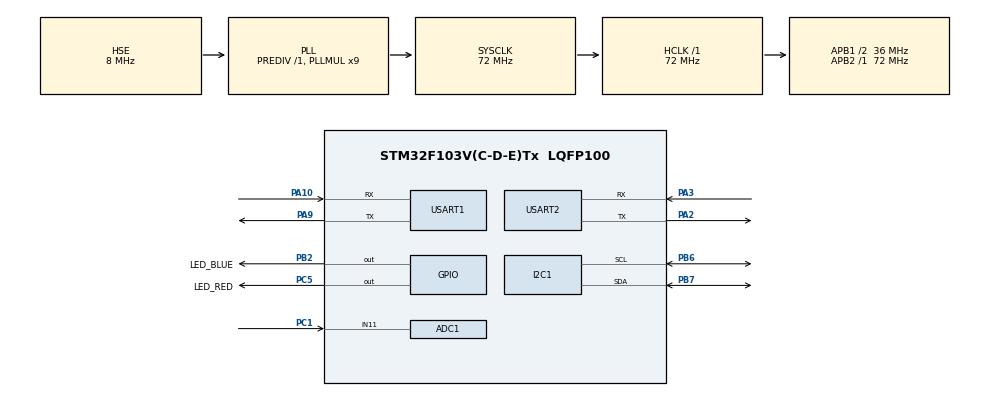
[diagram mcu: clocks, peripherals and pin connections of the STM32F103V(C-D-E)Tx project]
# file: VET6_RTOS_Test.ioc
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ADC1.Channel-2\#ChannelRegularConversion=ADC_CHANNEL_11
ADC1.NbrOfConversionFlag=1
ADC1.Rank-2\#ChannelRegularConversion=1
ADC1.SamplingTime-2\#ChannelRegularConversion=ADC_SAMPLETIME_1CYCLE_5
ADC1.master=1
Dma.Request0=USART1_RX
Dma.Request1=USART1_TX
Dma.Request2=USART2_RX
Dma.Request3=USART2_TX
Dma.USART1_RX.0.Direction=DMA_PERIPH_TO_MEMORY
Dma.USART1_RX.0.Instance=DMA1_Channel5
Dma.USART1_RX.0.MemDataAlignment=DMA_MDATAALIGN_BYTE
Dma.USART1_RX.0.MemInc=DMA_MINC_ENABLE
Dma.USART1_RX.0.Mode=DMA_NORMAL
Dma.USART1_RX.0.PeriphDataAlignment=DMA_PDATAALIGN_BYTE
Dma.USART1_RX.0.PeriphInc=DMA_PINC_DISABLE
Dma.USART1_RX.0.Priority=DMA_PRIORITY_LOW
Dma.USART1_TX.1.Direction=DMA_MEMORY_TO_PERIPH
Dma.USART1_TX.1.Instance=DMA1_Channel4
Dma.USART1_TX.1.MemDataAlignment=DMA_MDATAALIGN_BYTE
Dma.USART1_TX.1.MemInc=DMA_MINC_ENABLE
Dma.USART1_TX.1.Mode=DMA_NORMAL
Dma.USART1_TX.1.PeriphDataAlignment=DMA_PDATAALIGN_BYTE
Dma.USART1_TX.1.PeriphInc=DMA_PINC_DISABLE
Dma.USART1_TX.1.Priority=DMA_PRIORITY_LOW
Dma.USART2_RX.2.Direction=DMA_PERIPH_TO_MEMORY
Dma.USART2_RX.2.Instance=DMA1_Channel6
Dma.USART2_RX.2.MemDataAlignment=DMA_MDATAALIGN_BYTE
Dma.USART2_RX.2.MemInc=DMA_MINC_ENABLE
Dma.USART2_RX.2.Mode=DMA_NORMAL
Dma.USART2_RX.2.PeriphDataAlignment=DMA_PDATAALIGN_BYTE
Dma.USART2_RX.2.PeriphInc=DMA_PINC_DISABLE
Dma.USART2_RX.2.Priority=DMA_PRIORITY_LOW
Dma.USART2_TX.3.Direction=DMA_MEMORY_TO_PERIPH
Dma.USART2_TX.3.Instance=DMA1_Channel7
Dma.USART2_TX.3.MemDataAlignment=DMA_MDATAALIGN_BYTE
Dma.USART2_TX.3.MemInc=DMA_MINC_ENABLE
Dma.USART2_TX.3.Mode=DMA_NORMAL
Dma.USART2_TX.3.PeriphDataAlignment=DMA_PDATAALIGN_BYTE
Dma.USART2_TX.3.PeriphInc=DMA_PINC_DISABLE
Dma.USART2_TX.3.Priority=DMA_PRIORITY_LOW
FREERTOS.Tasks01=defaultTask,0,128,StartDefaultTask,Default,NULL,Dynamic,NULL,NULL;LEDTask,-3,128,LED_Task,Default,NULL,Dynamic,NULL,NULL;printfTask,-3,256,print_Task,Default,NULL,Dynamic,NULL,NULL
FREERTOS.configTOTAL_HEAP_SIZE=10240
I2C1.NoStretchMode=I2C_NOSTRETCH_DISABLE
Mcu.Family=STM32F1
Mcu.Name=STM32F103V(C-D-E)Tx
Mcu.Package=LQFP100
NVIC.DMA1_Channel4_IRQn=true\:5\:0\:false\:false\:true\:true\:false\:true\:true
NVIC.DMA1_Channel5_IRQn=true\:5\:0\:false\:false\:true\:true\:false\:true\:true
NVIC.DMA1_Channel6_IRQn=true\:5\:0\:false\:false\:true\:true\:false\:true\:true
NVIC.DMA1_Channel7_IRQn=true\:5\:0\:false\:false\:true\:true\:false\:true\:true
NVIC.I2C1_ER_IRQn=true\:5\:0\:false\:false\:true\:true\:true\:true\:true
NVIC.I2C1_EV_IRQn=true\:5\:0\:false\:false\:true\:true\:true\:true\:true
NVIC.PriorityGroup=NVIC_PRIORITYGROUP_4
NVIC.TIM7_IRQn=true\:15\:0\:false\:false\:true\:false\:false\:true\:true
NVIC.TimeBase=TIM7_IRQn
NVIC.TimeBaseIP=TIM7
NVIC.USART1_IRQn=true\:5\:0\:false\:false\:true\:true\:false\:true\:true
NVIC.USART2_IRQn=true\:5\:0\:false\:false\:true\:true\:false\:true\:true
OSC_IN.Mode=HSE-External-Oscillator
OSC_IN.Signal=RCC_OSC_IN
OSC_OUT.Mode=HSE-External-Oscillator
OSC_OUT.Signal=RCC_OSC_OUT
PA10.Mode=Asynchronous
PA10.Signal=USART1_RX
PA13.Mode=Serial_Wire
PA13.Signal=SYS_JTMS-SWDIO
PA14.Mode=Serial_Wire
PA14.Signal=SYS_JTCK-SWCLK
PA2.Mode=Asynchronous
PA2.Signal=USART2_TX
PA3.Mode=Asynchronous
PA3.Signal=USART2_RX
PA9.Mode=Asynchronous
PA9.Signal=USART1_TX
PB2.GPIO_Label=LED_BLUE
PB2.Signal=GPIO_Output
PB6.Mode=I2C
PB6.Signal=I2C1_SCL
PB7.Mode=I2C
PB7.Signal=I2C1_SDA
PC1.Signal=ADCx_IN11
PC5.GPIO_Label=LED_RED
PC5.Signal=GPIO_Output
ProjectManager.HeapSize=0x200
ProjectManager.StackSize=0x400
ProjectManager.TargetToolchain=MDK-ARM V5.32
RCC.ADCPresc=RCC_ADCPCLK2_DIV6
RCC.AHBFreq_Value=72000000
RCC.APB1CLKDivider=RCC_HCLK_DIV2
RCC.APB1Freq_Value=36000000
RCC.APB1TimFreq_Value=72000000
RCC.APB2Freq_Value=72000000
RCC.APB2TimFreq_Value=72000000
RCC.HCLKFreq_Value=72000000
RCC.PLLMUL=RCC_PLL_MUL9
RCC.PLLSourceVirtual=RCC_PLLSOURCE_HSE
RCC.SYSCLKFreq_VALUE=72000000
RCC.SYSCLKSource=RCC_SYSCLKSOURCE_PLLCLK
RCC.USBFreq_Value=72000000
SH.ADCx_IN11.0=ADC1_IN11,IN11
USART1.VirtualMode=VM_ASYNC
USART2.VirtualMode=VM_ASYNC
VP_FREERTOS_VS_CMSIS_V1.Mode=CMSIS_V1
VP_SYS_VS_tim7.Mode=TIM7
board=custom

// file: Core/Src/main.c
/* USER CODE BEGIN Header */
/**
  ******************************************************************************
  * @file           : main.c
  * @brief          : Main program body
  ******************************************************************************
  * @attention
  *
  * Copyright (c) 2025 STMicroelectronics.
  * All rights reserved.
  *
  * This software is licensed under terms that can be found in the LICENSE file
  * in the root directory of this software component.
  * If no LICENSE file comes with this software, it is provided AS-IS.
  *
  ******************************************************************************
  */
/* USER CODE END Header */
#include "main.h"
#include "cmsis_os.h"
#include "adc.h"
#include "dma.h"
#include "i2c.h"
#include "usart.h"
#include "gpio.h"

void SystemClock_Config(void);
void MX_FREERTOS_Init(void);

int main(void)
{

  /* MCU Configuration--------------------------------------------------------*/

  /* Reset of all peripherals, Initializes the Flash interface and the Systick. */
  HAL_Init();

  /* Configure the system clock */
  SystemClock_Config();

  /* Initialize all configured peripherals */
  MX_GPIO_Init();
  MX_DMA_Init();
  MX_USART1_UART_Init();
  MX_USART2_UART_Init();
  MX_ADC1_Init();
  MX_I2C1_Init();

  /* Call init function for freertos objects (in cmsis_os2.c) */
  MX_FREERTOS_Init();

  /* Start scheduler */
  osKernelStart();

  /* We should never get here as control is now taken by the scheduler */

  /* Infinite loop */
  while (1)
  {

  }
}

void SystemClock_Config(void)
{
  RCC_OscInitTypeDef RCC_OscInitStruct = {0};
  RCC_ClkInitTypeDef RCC_ClkInitStruct = {0};
  RCC_PeriphCLKInitTypeDef PeriphClkInit = {0};

  /** Initializes the RCC Oscillators according to the specified parameters
  * in the RCC_OscInitTypeDef structure.
  */
  RCC_OscInitStruct.OscillatorType = RCC_OSCILLATORTYPE_HSE;
  RCC_OscInitStruct.HSEState = RCC_HSE_ON;
  RCC_OscInitStruct.HSEPredivValue = RCC_HSE_PREDIV_DIV1;
  RCC_OscInitStruct.HSIState = RCC_HSI_ON;
  RCC_OscInitStruct.PLL.PLLState = RCC_PLL_ON;
  RCC_OscInitStruct.PLL.PLLSource = RCC_PLLSOURCE_HSE;
  RCC_OscInitStruct.PLL.PLLMUL = RCC_PLL_MUL9;
  if (HAL_RCC_OscConfig(&RCC_OscInitStruct) != HAL_OK)
  {
    Error_Handler();
  }

  /** Initializes the CPU, AHB and APB buses clocks
  */
  RCC_ClkInitStruct.ClockType = RCC_CLOCKTYPE_HCLK|RCC_CLOCKTYPE_SYSCLK
                              |RCC_CLOCKTYPE_PCLK1|RCC_CLOCKTYPE_PCLK2;
  RCC_ClkInitStruct.SYSCLKSource = RCC_SYSCLKSOURCE_PLLCLK;
  RCC_ClkInitStruct.AHBCLKDivider = RCC_SYSCLK_DIV1;
  RCC_ClkInitStruct.APB1CLKDivider = RCC_HCLK_DIV2;
  RCC_ClkInitStruct.APB2CLKDivider = RCC_HCLK_DIV1;

  if (HAL_RCC_ClockConfig(&RCC_ClkInitStruct, FLASH_LATENCY_2) != HAL_OK)
  {
    Error_Handler();
  }
  PeriphClkInit.PeriphClockSelection = RCC_PERIPHCLK_ADC;
  PeriphClkInit.AdcClockSelection = RCC_ADCPCLK2_DIV6;
  if (HAL_RCCEx_PeriphCLKConfig(&PeriphClkInit) != HAL_OK)
  {
    Error_Handler();
  }
}

void HAL_TIM_PeriodElapsedCallback(TIM_HandleTypeDef *htim)
{
  if (htim->Instance == TIM7)
  {
    HAL_IncTick();
  }
}

void Error_Handler(void)
{
  __disable_irq();
  while (1)
  {
  }
}

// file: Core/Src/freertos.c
/* USER CODE BEGIN Header */
/**
  ******************************************************************************
  * File Name          : freertos.c
  * Description        : Code for freertos applications
  ******************************************************************************
  * @attention
  *
  * Copyright (c) 2025 STMicroelectronics.
  * All rights reserved.
  *
  * This software is licensed under terms that can be found in the LICENSE file
  * in the root directory of this software component.
  * If no LICENSE file comes with this software, it is provided AS-IS.
  *
  ******************************************************************************
  */
/* USER CODE END Header */

#include "FreeRTOS.h"
#include "task.h"
#include "main.h"
#include "cmsis_os.h"

osThreadId defaultTaskHandle;
osThreadId LEDTaskHandle;
osThreadId printfTaskHandle;

void StartDefaultTask(void const * argument);
void LED_Task(void const * argument);
void print_Task(void const * argument);

void MX_FREERTOS_Init(void); /* (MISRA C 2004 rule 8.1) */

/* GetIdleTaskMemory prototype (linked to static allocation support) */
void vApplicationGetIdleTaskMemory( StaticTask_t **ppxIdleTaskTCBBuffer, StackType_t **ppxIdleTaskStackBuffer, uint32_t *pulIdleTaskStackSize );

/* USER CODE BEGIN GET_IDLE_TASK_MEMORY */
static StaticTask_t xIdleTaskTCBBuffer;
static StackType_t xIdleStack[configMINIMAL_STACK_SIZE];

void vApplicationGetIdleTaskMemory( StaticTask_t **ppxIdleTaskTCBBuffer, StackType_t **ppxIdleTaskStackBuffer, uint32_t *pulIdleTaskStackSize )
{
  *ppxIdleTaskTCBBuffer = &xIdleTaskTCBBuffer;
  *ppxIdleTaskStackBuffer = &xIdleStack[0];
  *pulIdleTaskStackSize = configMINIMAL_STACK_SIZE;
  /* place for user code */
}
/* USER CODE END GET_IDLE_TASK_MEMORY */

void MX_FREERTOS_Init(void) {

  /* Create the thread(s) */
  /* definition and creation of defaultTask */
  osThreadDef(defaultTask, StartDefaultTask, osPriorityNormal, 0, 128);
  defaultTaskHandle = osThreadCreate(osThread(defaultTask), NULL);

  /* definition and creation of LEDTask */
  osThreadDef(LEDTask, LED_Task, osPriorityIdle, 0, 128);
  LEDTaskHandle = osThreadCreate(osThread(LEDTask), NULL);

  /* definition and creation of printfTask */
  osThreadDef(printfTask, print_Task, osPriorityIdle, 0, 256);
  printfTaskHandle = osThreadCreate(osThread(printfTask), NULL);

}

void StartDefaultTask(void const * argument)
{
  for(;;)
  {
    osDelay(1);
  }
}

void LED_Task(void const * argument)
{
  /* USER CODE BEGIN LED_Task */
  /* Infinite loop */
  for(;;)
  {
		HAL_GPIO_TogglePin(LED_BLUE_GPIO_Port,LED_BLUE_Pin);
    osDelay(500);
		HAL_GPIO_TogglePin(LED_RED_GPIO_Port,LED_RED_Pin);
		HAL_GPIO_TogglePin(LED_BLUE_GPIO_Port,LED_BLUE_Pin);
		osDelay(500);
  }
  /* USER CODE END LED_Task */
}

void print_Task(void const * argument)
{
  for(;;)
  {
    osDelay(1);
  }
}
